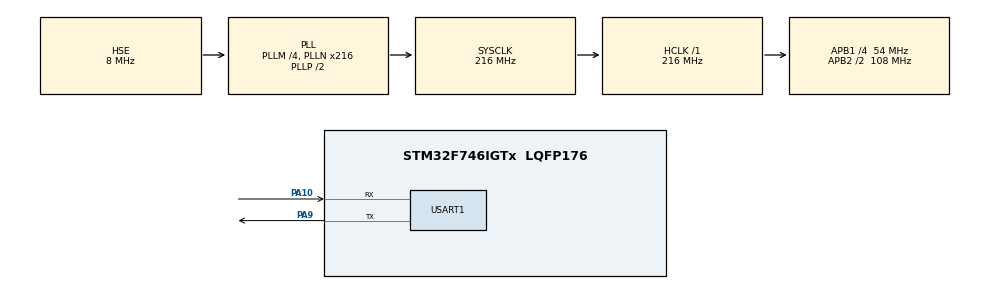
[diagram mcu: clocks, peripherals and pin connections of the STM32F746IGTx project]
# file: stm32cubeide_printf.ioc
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Dma.Request0=USART1_TX
Dma.USART1_TX.0.Direction=DMA_MEMORY_TO_PERIPH
Dma.USART1_TX.0.FIFOMode=DMA_FIFOMODE_DISABLE
Dma.USART1_TX.0.Instance=DMA2_Stream7
Dma.USART1_TX.0.MemDataAlignment=DMA_MDATAALIGN_BYTE
Dma.USART1_TX.0.MemInc=DMA_MINC_ENABLE
Dma.USART1_TX.0.Mode=DMA_NORMAL
Dma.USART1_TX.0.PeriphDataAlignment=DMA_PDATAALIGN_BYTE
Dma.USART1_TX.0.PeriphInc=DMA_PINC_DISABLE
Dma.USART1_TX.0.Priority=DMA_PRIORITY_HIGH
Mcu.Family=STM32F7
Mcu.Name=STM32F746IGTx
Mcu.Package=LQFP176
NVIC.DMA2_Stream7_IRQn=true\:0\:0\:false\:false\:true\:false\:true
NVIC.PriorityGroup=NVIC_PRIORITYGROUP_4
NVIC.USART1_IRQn=true\:0\:0\:false\:false\:true\:true\:true
PA10.Mode=Asynchronous
PA10.Signal=USART1_RX
PA9.Mode=Asynchronous
PA9.Signal=USART1_TX
PH0/OSC_IN.Mode=HSE-External-Oscillator
PH0/OSC_IN.Signal=RCC_OSC_IN
PH1/OSC_OUT.Mode=HSE-External-Oscillator
PH1/OSC_OUT.Signal=RCC_OSC_OUT
ProjectManager.HeapSize=0x200
ProjectManager.StackSize=0x400
ProjectManager.TargetToolchain=STM32CubeIDE
RCC.AHBFreq_Value=216000000
RCC.APB1CLKDivider=RCC_HCLK_DIV4
RCC.APB1Freq_Value=54000000
RCC.APB1TimFreq_Value=108000000
RCC.APB2CLKDivider=RCC_HCLK_DIV2
RCC.APB2Freq_Value=108000000
RCC.APB2TimFreq_Value=216000000
RCC.CortexFreq_Value=216000000
RCC.HCLKFreq_Value=216000000
RCC.HSE_VALUE=8000000
RCC.HSI_VALUE=16000000
RCC.LSE_VALUE=32768
RCC.PLLM=4
RCC.PLLN=216
RCC.PLLSourceVirtual=RCC_PLLSOURCE_HSE
RCC.SYSCLKFreq_VALUE=216000000
RCC.SYSCLKSource=RCC_SYSCLKSOURCE_PLLCLK
RCC.USBFreq_Value=216000000
RCC.VCOOutputFreq_Value=432000000
USART1.VirtualMode-Asynchronous=VM_ASYNC
board=custom

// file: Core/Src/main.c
/* USER CODE BEGIN Header */
/**
  ******************************************************************************
  * @file           : main.c
  * @brief          : Main program body
  ******************************************************************************
  * @attention
  *
  * <h2><center>&copy; Copyright (c) 2020 STMicroelectronics.
  * All rights reserved.</center></h2>
  *
  * This software component is licensed by ST under BSD 3-Clause license,
  * the "License"; You may not use this file except in compliance with the
  * License. You may obtain a copy of the License at:
  *                        opensource.org/licenses/BSD-3-Clause
  *
  ******************************************************************************
  */
/* USER CODE END Header */

#include "main.h"

/* USER CODE BEGIN Includes */
#include <stdio.h>
/* USER CODE END Includes */

UART_HandleTypeDef huart1;
DMA_HandleTypeDef hdma_usart1_tx;

void SystemClock_Config(void);
static void MX_GPIO_Init(void);
static void MX_DMA_Init(void);
static void MX_USART1_UART_Init(void);

int main(void)
{

  /* MCU Configuration--------------------------------------------------------*/

  /* Reset of all peripherals, Initializes the Flash interface and the Systick. */
  HAL_Init();

  /* Configure the system clock */
  SystemClock_Config();

  /* Initialize all configured peripherals */
  MX_GPIO_Init();
  MX_DMA_Init();
  MX_USART1_UART_Init();

  /* Infinite loop */
  /* USER CODE BEGIN WHILE */
  while (1)
  {
	  printf("debug string test\n\r");
	  HAL_Delay(500);
    /* USER CODE END WHILE */

  }
}

void SystemClock_Config(void)
{
  RCC_OscInitTypeDef RCC_OscInitStruct = {0};
  RCC_ClkInitTypeDef RCC_ClkInitStruct = {0};
  RCC_PeriphCLKInitTypeDef PeriphClkInitStruct = {0};

  /** Configure the main internal regulator output voltage
  */
  __HAL_RCC_PWR_CLK_ENABLE();
  __HAL_PWR_VOLTAGESCALING_CONFIG(PWR_REGULATOR_VOLTAGE_SCALE1);
  /** Initializes the CPU, AHB and APB busses clocks
  */
  RCC_OscInitStruct.OscillatorType = RCC_OSCILLATORTYPE_HSE;
  RCC_OscInitStruct.HSEState = RCC_HSE_ON;
  RCC_OscInitStruct.PLL.PLLState = RCC_PLL_ON;
  RCC_OscInitStruct.PLL.PLLSource = RCC_PLLSOURCE_HSE;
  RCC_OscInitStruct.PLL.PLLM = 4;
  RCC_OscInitStruct.PLL.PLLN = 216;
  RCC_OscInitStruct.PLL.PLLP = RCC_PLLP_DIV2;
  RCC_OscInitStruct.PLL.PLLQ = 2;
  if (HAL_RCC_OscConfig(&RCC_OscInitStruct) != HAL_OK)
  {
    Error_Handler();
  }
  /** Activate the Over-Drive mode
  */
  if (HAL_PWREx_EnableOverDrive() != HAL_OK)
  {
    Error_Handler();
  }
  /** Initializes the CPU, AHB and APB busses clocks
  */
  RCC_ClkInitStruct.ClockType = RCC_CLOCKTYPE_HCLK|RCC_CLOCKTYPE_SYSCLK
                              |RCC_CLOCKTYPE_PCLK1|RCC_CLOCKTYPE_PCLK2;
  RCC_ClkInitStruct.SYSCLKSource = RCC_SYSCLKSOURCE_PLLCLK;
  RCC_ClkInitStruct.AHBCLKDivider = RCC_SYSCLK_DIV1;
  RCC_ClkInitStruct.APB1CLKDivider = RCC_HCLK_DIV4;
  RCC_ClkInitStruct.APB2CLKDivider = RCC_HCLK_DIV2;

  if (HAL_RCC_ClockConfig(&RCC_ClkInitStruct, FLASH_LATENCY_7) != HAL_OK)
  {
    Error_Handler();
  }
  PeriphClkInitStruct.PeriphClockSelection = RCC_PERIPHCLK_USART1;
  PeriphClkInitStruct.Usart1ClockSelection = RCC_USART1CLKSOURCE_PCLK2;
  if (HAL_RCCEx_PeriphCLKConfig(&PeriphClkInitStruct) != HAL_OK)
  {
    Error_Handler();
  }
}

static void MX_USART1_UART_Init(void)
{

  huart1.Instance = USART1;
  huart1.Init.BaudRate = 115200;
  huart1.Init.WordLength = UART_WORDLENGTH_8B;
  huart1.Init.StopBits = UART_STOPBITS_1;
  huart1.Init.Parity = UART_PARITY_NONE;
  huart1.Init.Mode = UART_MODE_TX_RX;
  huart1.Init.HwFlowCtl = UART_HWCONTROL_NONE;
  huart1.Init.OverSampling = UART_OVERSAMPLING_16;
  huart1.Init.OneBitSampling = UART_ONE_BIT_SAMPLE_DISABLE;
  huart1.AdvancedInit.AdvFeatureInit = UART_ADVFEATURE_NO_INIT;
  if (HAL_UART_Init(&huart1) != HAL_OK)
  {
    Error_Handler();
  }

}

static void MX_DMA_Init(void)
{

  /* DMA controller clock enable */
  __HAL_RCC_DMA2_CLK_ENABLE();

  /* DMA interrupt init */
  /* DMA2_Stream7_IRQn interrupt configuration */
  HAL_NVIC_SetPriority(DMA2_Stream7_IRQn, 0, 0);
  HAL_NVIC_EnableIRQ(DMA2_Stream7_IRQn);

}

static void MX_GPIO_Init(void)
{

  /* GPIO Ports Clock Enable */
  __HAL_RCC_GPIOH_CLK_ENABLE();
  __HAL_RCC_GPIOA_CLK_ENABLE();

}

/* USER CODE BEGIN 4 */
#ifdef __GNUC__
#define PUTCHAR_PROTOTYPE int __io_putchar(int ch)
#else
  #define PUTCHAR_PROTOTYPE int fputc(int ch, FILE *f)
#endif /* __GNUC__ */

#define STR_SIZE 255

uint8_t str[STR_SIZE]={0};

PUTCHAR_PROTOTYPE
{
	static uint16_t index = 0 ;

	str[index++] = ch;
	if(ch=='\n')
	{
		HAL_UART_Transmit_DMA(&huart1,str,index);
		index = 0;
	}
	return ch;
}
/* USER CODE END 4 */

void Error_Handler(void)
{
}

/************************ (C) COPYRIGHT STMicroelectronics *****END OF FILE****/
